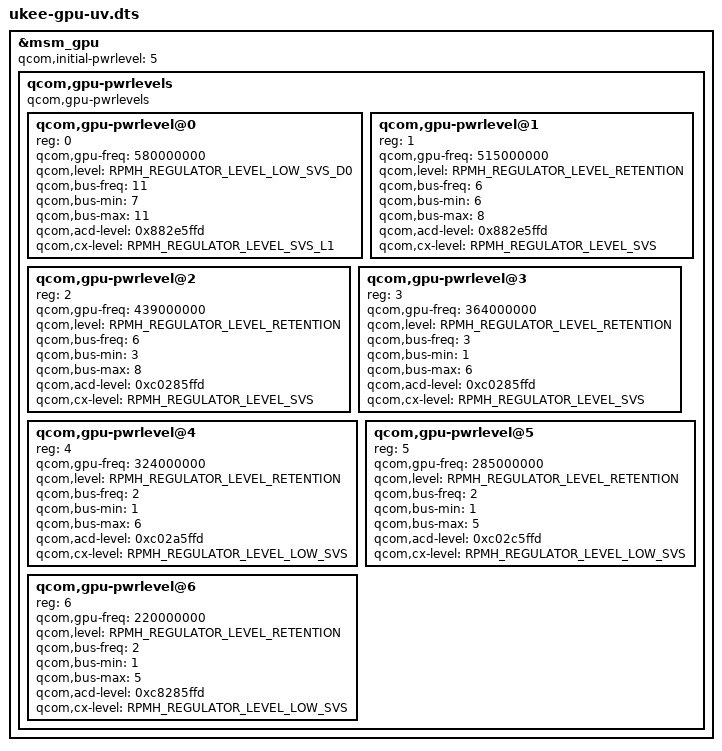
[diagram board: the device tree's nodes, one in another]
/*
 * DoraCore: ukee.dtb with an Adreno 725 undervolt (stock frequencies, lower GPU voltage)
 * power level table, from the KonaBess profile "default freqs, only undervolt | SD 7+ GEN 2".
 * Generated by tools/gen-gpu-profiles.py; only the GPU (GX) rail
 * levels change, CX votes stay as stock. Running the GPU outside the
 * stock table may crash, freeze or damage the device.
 */

#include "ukee.dts"

&msm_gpu {
	/delete-node/ qcom,gpu-pwrlevels;
};

&msm_gpu {
	qcom,initial-pwrlevel = <5>;

	qcom,gpu-pwrlevels {
		#address-cells = <1>;
		#size-cells = <0>;

		compatible = "qcom,gpu-pwrlevels";

		/* 580 MHz (stock SVS_L0, profile level 57) */
		qcom,gpu-pwrlevel@0 {
			reg = <0>;
			qcom,gpu-freq = <580000000>;
			qcom,level = <RPMH_REGULATOR_LEVEL_LOW_SVS_D0>;

			qcom,bus-freq = <11>;
			qcom,bus-min = <7>;
			qcom,bus-max = <11>;

			qcom,acd-level = <0x882e5ffd>;
			qcom,cx-level = <RPMH_REGULATOR_LEVEL_SVS_L1>;
		};

		/* 515 MHz (stock SVS, profile level 1) */
		qcom,gpu-pwrlevel@1 {
			reg = <1>;
			qcom,gpu-freq = <515000000>;
			qcom,level = <RPMH_REGULATOR_LEVEL_RETENTION>;

			qcom,bus-freq = <6>;
			qcom,bus-min = <6>;
			qcom,bus-max = <8>;

			qcom,acd-level = <0x882e5ffd>;
			qcom,cx-level = <RPMH_REGULATOR_LEVEL_SVS>;
		};

		/* 439 MHz (stock LOW_SVS_L2, profile level 1) */
		qcom,gpu-pwrlevel@2 {
			reg = <2>;
			qcom,gpu-freq = <439000000>;
			qcom,level = <RPMH_REGULATOR_LEVEL_RETENTION>;

			qcom,bus-freq = <6>;
			qcom,bus-min = <3>;
			qcom,bus-max = <8>;

			qcom,acd-level = <0xc0285ffd>;
			qcom,cx-level = <RPMH_REGULATOR_LEVEL_SVS>;
		};

		/* 364 MHz (stock LOW_SVS_L1, profile level 1) */
		qcom,gpu-pwrlevel@3 {
			reg = <3>;
			qcom,gpu-freq = <364000000>;
			qcom,level = <RPMH_REGULATOR_LEVEL_RETENTION>;

			qcom,bus-freq = <3>;
			qcom,bus-min = <1>;
			qcom,bus-max = <6>;

			qcom,acd-level = <0xc0285ffd>;
			qcom,cx-level = <RPMH_REGULATOR_LEVEL_SVS>;
		};

		/* 324 MHz (stock LOW_SVS, profile level 1) */
		qcom,gpu-pwrlevel@4 {
			reg = <4>;
			qcom,gpu-freq = <324000000>;
			qcom,level = <RPMH_REGULATOR_LEVEL_RETENTION>;

			qcom,bus-freq = <2>;
			qcom,bus-min = <1>;
			qcom,bus-max = <6>;

			qcom,acd-level = <0xc02a5ffd>;
			qcom,cx-level = <RPMH_REGULATOR_LEVEL_LOW_SVS>;
		};

		/* 285 MHz (stock LOW_SVS_D1, profile level 1) */
		qcom,gpu-pwrlevel@5 {
			reg = <5>;
			qcom,gpu-freq = <285000000>;
			qcom,level = <RPMH_REGULATOR_LEVEL_RETENTION>;

			qcom,bus-freq = <2>;
			qcom,bus-min = <1>;
			qcom,bus-max = <5>;

			qcom,acd-level = <0xc02c5ffd>;
			qcom,cx-level = <RPMH_REGULATOR_LEVEL_LOW_SVS>;
		};

		/* 220 MHz (stock MIN_SVS, profile level 1) */
		qcom,gpu-pwrlevel@6 {
			reg = <6>;
			qcom,gpu-freq = <220000000>;
			qcom,level = <RPMH_REGULATOR_LEVEL_RETENTION>;

			qcom,bus-freq = <2>;
			qcom,bus-min = <1>;
			qcom,bus-max = <5>;

			qcom,acd-level = <0xc8285ffd>;
			qcom,cx-level = <RPMH_REGULATOR_LEVEL_LOW_SVS>;
		};
	};
};
